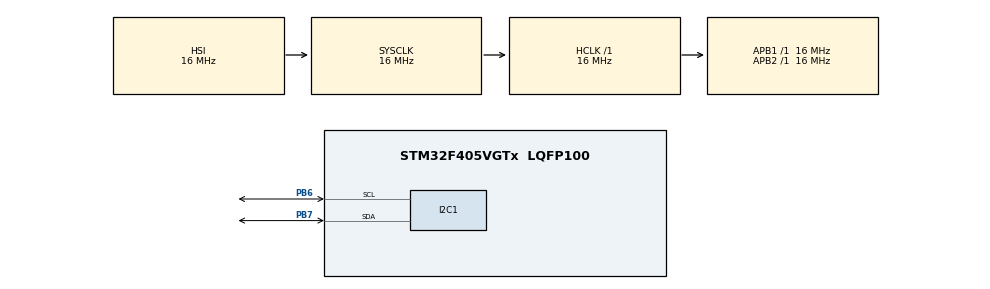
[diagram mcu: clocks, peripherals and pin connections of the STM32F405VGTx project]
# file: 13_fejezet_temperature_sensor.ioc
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Mcu.Family=STM32F4
PH0-OSC_IN.Signal=RCC_OSC_IN
RCC.CortexFreq_Value=16000000
ProjectManager.StackSize=0x400
PA13.Signal=SYS_JTMS-SWDIO
ProjectManager.TargetToolchain=STM32CubeIDE
PB6.Signal=I2C1_SCL
PB6.Mode=I2C
RCC.LSE_VALUE=32768
RCC.AHBFreq_Value=16000000
PH0-OSC_IN.Mode=HSE-External-Oscillator
RCC.HSE_VALUE=8000000
PB3.Mode=JTAG_4_pins
board=custom
RCC.VCOOutputFreq_Value=192000000
PA15.Mode=JTAG_4_pins
RCC.APB2Freq_Value=16000000
PA14.Mode=JTAG_4_pins
PH1-OSC_OUT.Signal=RCC_OSC_OUT
PB7.Signal=I2C1_SDA
PA13.Mode=JTAG_4_pins
Mcu.Name=STM32F405VGTx
PH1-OSC_OUT.Mode=HSE-External-Oscillator
PB3.Signal=SYS_JTDO-SWO
RCC.SYSCLKFreq_VALUE=16000000
Mcu.Package=LQFP100
PB7.Mode=I2C
PA14.Signal=SYS_JTCK-SWCLK
PA15.Signal=SYS_JTDI
ProjectManager.HeapSize=0x200
RCC.HSI_VALUE=16000000
NVIC.PriorityGroup=NVIC_PRIORITYGROUP_4
RCC.APB1Freq_Value=16000000

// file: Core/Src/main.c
/* USER CODE BEGIN Header */
/**
  ******************************************************************************
  * @file           : main.c
  * @brief          : Main program body
  ******************************************************************************
  * @attention
  *
  * <h2><center>&copy; Copyright (c) 2020 STMicroelectronics.
  * All rights reserved.</center></h2>
  *
  * This software component is licensed by ST under BSD 3-Clause license,
  * the "License"; You may not use this file except in compliance with the
  * License. You may obtain a copy of the License at:
  *                        opensource.org/licenses/BSD-3-Clause
  *
  ******************************************************************************
  */
/* USER CODE END Header */

#include "main.h"
#include "i2c.h"
#include "gpio.h"

/* USER CODE BEGIN Includes */

#include "OLED.h"
#include "temperature_sensor.h"
#include <stdio.h>

/* USER CODE END Includes */

void SystemClock_Config(void);

int main(void)
{

  /* MCU Configuration--------------------------------------------------------*/

  /* Reset of all peripherals, Initializes the Flash interface and the Systick. */
  HAL_Init();

  /* Configure the system clock */
  SystemClock_Config();

  /* Initialize all configured peripherals */
  MX_GPIO_Init();
  MX_I2C1_Init();
  /* USER CODE BEGIN 2 */

  // OLED kijelző inicializálása, a mért hőmérséklet kijelzése
  OLED_Init();

  // Változók a mért hőmérséklet tárolására
  float lm_temperature;
  uint16_t lm_temperature_int;
  uint16_t lm_temperature_frac;

     // Character array for displaying the measured hih_temperature
     // Karaktertömb a mért hőmérséklet kijelzésére
  char lm_temperature_char[20];

  /*
   * Túlhőmérsékleti leállítás üzemmód használata
   * (LED az LM75A IC mellett)
   */
  // Túlhőmérsékleti küszöbérték (bekapcsolás) beállítása 28 Celsius-fokra
  LM75A_SetOSTemperature(28);
  // Túlhőmérsékleti hiszterézis (kikapcsolás) beállítása 27 Celsius-fokra
  LM75A_SetOSHysteresis(27);

  /* USER CODE END 2 */

  /* Infinite loop */
  /* USER CODE BEGIN WHILE */
  while (1)
  {

	  LM75A_GetTemperature(&lm_temperature);

	  			// Float érték sztringgé alakítása. Az egész és a tört rész külön van kezelve.
	  lm_temperature_int = (uint16_t)lm_temperature;
	  lm_temperature_frac = (uint16_t)(lm_temperature * 100) - 100 * (uint16_t)lm_temperature;
	  sprintf(lm_temperature_char, "%d.%d C", lm_temperature_int, lm_temperature_frac);

	  			// Páratartalom érzékelő

	  			// Kijelző frissítés
	  			OLED_Fill(Black);
	  			OLED_SetCursor(2, 0);
	  			OLED_WriteString("LM75:", Font_7x10, White);
	  		    OLED_SetCursor(2, 10);
	  		    OLED_WriteString(lm_temperature_char, Font_7x10, White);
	  		    // A °C jelben a kör pozíciója a kijelzett szám törtrészének hosszától függ
	  		    if (lm_temperature_char[4] == ' ')
	  		    {
	  		    	OLED_DrawCircle(33, 12, 2, White);
	  		    }
	  		    else
	  		    {
	  		    	OLED_DrawCircle(40, 12, 2, White);
	  		    }
	  			OLED_SetCursor(2, 20);
	  			OLED_WriteString("HIH8120:", Font_7x10, White);
	  		    OLED_SetCursor(2, 30);
	  		    OLED_WriteString(lm_temperature_char, Font_7x10, White);
	  		    // A °C jelben a kör pozíciója a kijelzett szám törtrészének hosszától függ
	  		    if (lm_temperature_char[4] == ' ')
	  		    {
	  		    	OLED_DrawCircle(33, 32, 2, White);
	  		    }
	  		    else
	  		    {
	  		    	OLED_DrawCircle(40, 32, 2, White);
	  		    }
	  		  OLED_UpdateScreen();
	  		}

    /* USER CODE END WHILE */

  }

void SystemClock_Config(void)
{
  RCC_OscInitTypeDef RCC_OscInitStruct = {0};
  RCC_ClkInitTypeDef RCC_ClkInitStruct = {0};

  /** Configure the main internal regulator output voltage
  */
  __HAL_RCC_PWR_CLK_ENABLE();
  __HAL_PWR_VOLTAGESCALING_CONFIG(PWR_REGULATOR_VOLTAGE_SCALE1);
  /** Initializes the CPU, AHB and APB busses clocks
  */
  RCC_OscInitStruct.OscillatorType = RCC_OSCILLATORTYPE_HSI;
  RCC_OscInitStruct.HSIState = RCC_HSI_ON;
  RCC_OscInitStruct.HSICalibrationValue = RCC_HSICALIBRATION_DEFAULT;
  RCC_OscInitStruct.PLL.PLLState = RCC_PLL_NONE;
  if (HAL_RCC_OscConfig(&RCC_OscInitStruct) != HAL_OK)
  {
    Error_Handler();
  }
  /** Initializes the CPU, AHB and APB busses clocks
  */
  RCC_ClkInitStruct.ClockType = RCC_CLOCKTYPE_HCLK|RCC_CLOCKTYPE_SYSCLK
                              |RCC_CLOCKTYPE_PCLK1|RCC_CLOCKTYPE_PCLK2;
  RCC_ClkInitStruct.SYSCLKSource = RCC_SYSCLKSOURCE_HSI;
  RCC_ClkInitStruct.AHBCLKDivider = RCC_SYSCLK_DIV1;
  RCC_ClkInitStruct.APB1CLKDivider = RCC_HCLK_DIV1;
  RCC_ClkInitStruct.APB2CLKDivider = RCC_HCLK_DIV1;

  if (HAL_RCC_ClockConfig(&RCC_ClkInitStruct, FLASH_LATENCY_0) != HAL_OK)
  {
    Error_Handler();
  }
}

void Error_Handler(void)
{
}

/************************ (C) COPYRIGHT STMicroelectronics *****END OF FILE****/
